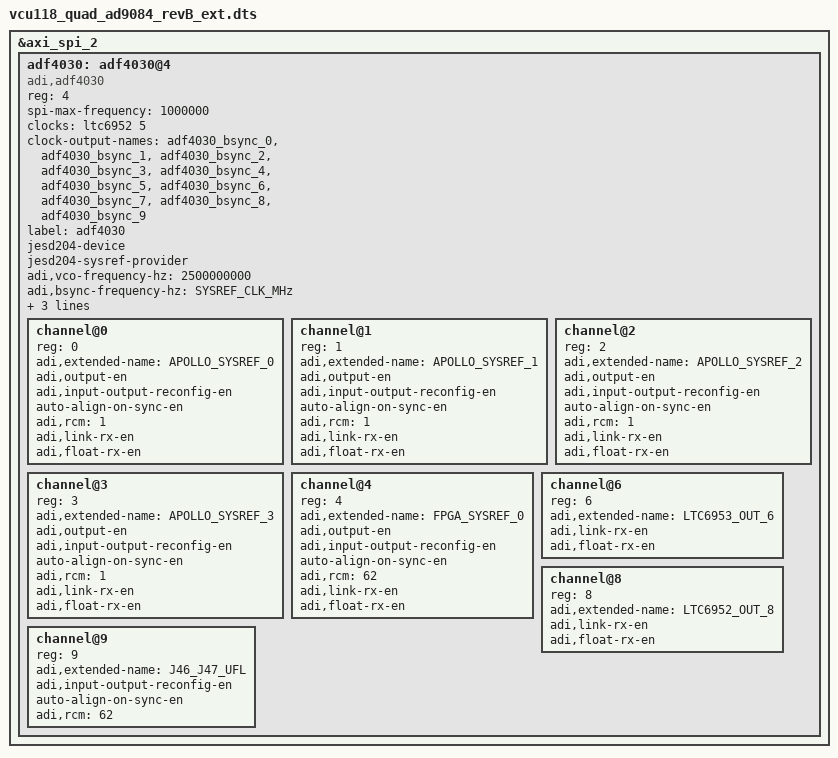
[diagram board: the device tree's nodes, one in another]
// SPDX-License-Identifier: GPL-2.0
/*
 * Analog Devices Quad-AD9084 RevB
 * https://wiki.analog.com/resources/tools-software/linux-drivers/iio-mxfe/ad9084
 * https://wiki.analog.com/resources/eval/user-guides/ad9084_fmca_ebz/ad9084_fmca_ebz_hdl
 *
 * hdl_project: <quad_apollo/vcu118>
 * board_revision: <Rev.B>
 *
 * Copyright (C) 2024 Analog Devices Inc.
 */

#include "vcu118_quad_ad9084_revB.dts"

&axi_spi_2 {

	/delete-node/ adf4030;

	adf4030: adf4030@4 {
		#clock-cells = <1>;
		compatible = "adi,adf4030";
		reg = <4>;

		#address-cells = <1>;
		#size-cells = <0>;
		#io-channel-cells = <1>;


		spi-max-frequency = <1000000>;
		clocks = <&ltc6952 5>;
		clock-names = "refin";
		clock-output-names = "adf4030_bsync_0", "adf4030_bsync_1",
			"adf4030_bsync_2", "adf4030_bsync_3", "adf4030_bsync_4",
			"adf4030_bsync_5", "adf4030_bsync_6", "adf4030_bsync_7",
			"adf4030_bsync_8", "adf4030_bsync_9";
		label = "adf4030";

		jesd204-device;
		#jesd204-cells = <2>;
		jesd204-sysref-provider;

		adi,vco-frequency-hz = <2500000000>; /* 2.5 GHz */
		adi,bsync-frequency-hz = <SYSREF_CLK_MHz>;
		adi,bsync-autoalign-reference-channel = <9>; /* J46_J47_UFL */
		adi,bsync-autoalign-iteration-count = <6>;
		adi,bsync-secondary-frequency-hz = <12500000>; /* 12.5 MHz */

		channel@0 {
			reg = <0>;
			adi,extended-name = "APOLLO_SYSREF_0";
			adi,output-en;
			adi,input-output-reconfig-en;
			auto-align-on-sync-en;
			adi,rcm = <1>;
			adi,link-rx-en;
			adi,float-rx-en;
		};
		channel@1 {
			reg = <1>;
			adi,extended-name = "APOLLO_SYSREF_1";
			adi,output-en;
			adi,input-output-reconfig-en;
			auto-align-on-sync-en;
			adi,rcm = <1>;
			adi,link-rx-en;
			adi,float-rx-en;
		};
		channel@2 {
			reg = <2>;
			adi,extended-name = "APOLLO_SYSREF_2";
			adi,output-en;
			adi,input-output-reconfig-en;
			auto-align-on-sync-en;
			adi,rcm = <1>;
			adi,link-rx-en;
			adi,float-rx-en;
		};
		channel@3 {
			reg = <3>;
			adi,extended-name = "APOLLO_SYSREF_3";
			adi,output-en;
			adi,input-output-reconfig-en;
			auto-align-on-sync-en;
			adi,rcm = <1>;
			adi,link-rx-en;
			adi,float-rx-en;
		};
		channel@4 {
			reg = <4>;
			adi,extended-name = "FPGA_SYSREF_0"; /* RES rotate option for J40/J41 U.FL output */
			adi,output-en;
			adi,input-output-reconfig-en;
			auto-align-on-sync-en;
			adi,rcm = <62>;
			adi,link-rx-en;
			adi,float-rx-en;
		};
		// channel@5 {
		// 	reg = <5>;
		// 	adi,extended-name = "FPGA_SYSREF_1"; /* RES rotate option for J42/J43 U.FL output */
		// 	adi,output-en;
		// 	adi,input-output-reconfig-en;
		// 	adi,rcm = <62>;
		// };
		channel@6 {
			reg = <6>;
			adi,extended-name = "LTC6953_OUT_6";
			adi,link-rx-en;
			adi,float-rx-en;
		};
		/* BSYNC7 unused */
		channel@8 {
			reg = <8>;
			adi,extended-name = "LTC6952_OUT_8";
			adi,link-rx-en;
			adi,float-rx-en;
		};
		channel@9 {
			reg = <9>;
			adi,extended-name = "J46_J47_UFL";
			//adi,output-en;
			adi,input-output-reconfig-en;
			auto-align-on-sync-en;
			adi,rcm = <62>;
		};
	};
};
